# MMCSD1_COMMON_0_CTL_CFG register map
Vendor: Texas Instruments
Registers are 16-bit, read-write, reset 0x0 unless marked. A register's access mark holds for its fields unless they carry their own. Offsets are as the file gives them; [hi:lo] are bit positions; lines under a group give offsets from that group; {n}, {i} and the like mark numbered series.

## MMCSD1_COMMON_0_CTL_CFG (part 3 of 3)
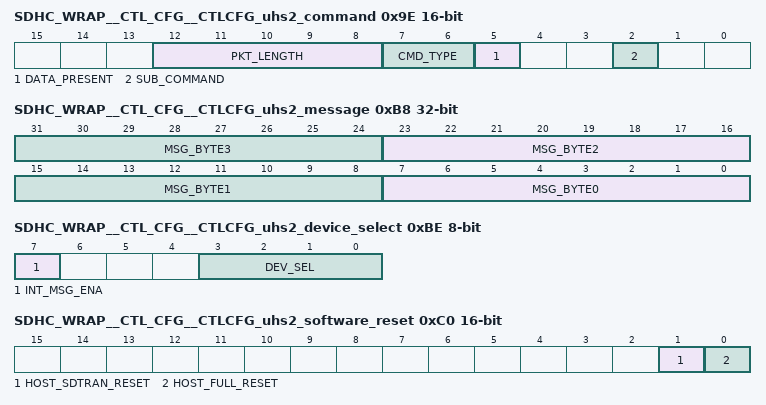
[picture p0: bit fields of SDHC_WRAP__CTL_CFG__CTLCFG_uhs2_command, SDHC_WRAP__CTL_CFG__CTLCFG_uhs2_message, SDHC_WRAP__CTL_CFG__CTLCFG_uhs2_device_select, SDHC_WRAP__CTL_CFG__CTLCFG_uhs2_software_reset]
0x9E SDHC_WRAP__CTL_CFG__CTLCFG_uhs2_command
  [12:8] PKT_LENGTH — A command packet length, which is set in the UHS-II Command Packet register, is set to this register. 00011b - 00000b - 3-0 Bytes [Not used] 00100b - 4 Bytes .......... ...... 10100b - 20 Bytes 11111b 10101b
  [7:6] CMD_TYPE — This field is used to distinguish a spe-cific command like abort command. If this field is set to 00b, the UHS-II RES Packet is stored in UHS-II Response register [0B3h-0A0h]. To avoid overwrit-ing the UHS-II Response register, when this filed is set to 01b, the RES Packet [4 bytes length] of TRANS_ABORT CCMD is stored in the Response regis-ter [013h-010h] and when this filed is set to 10b, the RES Packet [8 bytes length] of memory or SDIO abort com-mand [CMD12 or SDIO Abort com-mand] is stored in the Response register [01Fh-018h]. When this filed is set to 11b, Host Controller controls lane to go into dormant state. '00' Normal Command '01' TRANS_ABORT CCMD '10' CMD12 or SDIO Abort Command '11' Go Dormant Command
  [5] DATA_PRESENT — This bit specifies whether the command is accompanied by data packet.
  [2] SUB_COMMAND — This bit is added from Version 4.10 to distinguish a main command or sub command [Refer to Section 1.17].When issuing a main command, this bit is set to 0 and when issuing a sub com-mand, this bit is set to 1. Setting of this bit is checked by Sub Command Status in the Present State register.
0xA0 SDHC_WRAP__CTL_CFG__CTLCFG_uhs2_response 8-bit ro
  [7:0] RESP_PKT_BYTE — Host Controller saves received UHS-II RES Packet image to this register except the response of an abort command.
0xB4 SDHC_WRAP__CTL_CFG__CTLCFG_uhs2_message_select 8-bit
  [1:0] MSG_SEL — Host Controller holds 4 MSG packets in FIFO buffer.One of 4 MSGs can be read from the UHS-II MSG register [0BB-0B8h] by setting this register.[Assumed for debug usage.] '00' The latest MSG '01' One MSG before '10' Two MSGs before '11' Three MSGs before
0xB8 SDHC_WRAP__CTL_CFG__CTLCFG_uhs2_message 32-bit ro
  [8n+7:8n] MSG_BYTE{n} (n=0..3) — Host Controller holds 4 MSG packets in FIFO buffer. One of 4 MSGs [length is 4 bytes] can be read fromthis register by setting UHS-II MSG Select register. Usually 2 duplicate MSG packets are sent from/toUHS-II card. One of these 2 MSG packets which Host Controller recognizes as valid one is stored in theUHS-II MSG Register.
0xBC SDHC_WRAP__CTL_CFG__CTLCFG_uhs2_device_intr_status access not given
  [15:0] DEV_INT_STS — This register shows receipt of INT MSG from which device and is effective when INT MSG Enable is set to 1 in the UHS- II Device Select register. On receiving INT MSG from a device, Host Controller saves the INT MSG to UHS-II Device Interrupt Code register. A bit of this register, which is corre- spondent to Device ID, is set to 1 and generate Card Interrupt in Normal Interrupt Status register. Writing a bit to 1 clears the status bit [interrupt is treated] and writing a bit to 0 keeps the status value [interrupt is untreated]. If INT MSG Enable is set to 0, this register is cleared to 0 and Host Controller ignores receipt of INT MSG. Effective bit range of this register is determined by Number of Devices Supported in the UHS-II General Capabilities regis-ter. If N devices are supported, bits 1 to N are effective. Then Device ID is supposed to be assigned from 1 sequentially at the UHS-II Initialization. A bit of unsupported Device ID in this register shall be indicated to 0. D00 - Not used [Reserved] D01 - Setting 1 means INT MSG is received from Device ID 1 D02 - Setting 1 means INT MSG is received from Device ID 2 .... ..... D15 - Setting 1 means INT MSG is received from Device ID 15 (access R/W1TC)
0xBE SDHC_WRAP__CTL_CFG__CTLCFG_uhs2_device_select 8-bit
  [7] INT_MSG_ENA — This bit enables receipt of INT MSG. If this bit is set to 1,receipt of INT MSG is informed by Card Interrupt in the Nor-mal Interrupt Status register. If this bit is set to 0, Host Con-troller ignores receipt of INT MSG and may not set the UHS-II Device Interrupt Code register. Support of INT MSG Interrupt is optional. If trying to set this bit to 1 but still this bit is read 0, INT MSG Interrupt is not sup-ported by the Host Controller. In this case, UHS-II Device Interrupt Status register always shall be read 0 and UHS-II Device Interrupt Code register may not be implemented. '0' Disabled '1' Enabled
  [3:0] DEV_SEL — Host Controller holds an INT MSG packet per device. One of INT MSGs [up to 15] can be selected by this field and read from the UHS-II Device Interrupt Code Register [0BFh]. This field is effective when INT MSG Enable is set to 1. The number of devices implemented in the Host Controller is indicated by Number of Devices supported in the UHS-II General Capabilities register. 0h Unselected [Default] 1h INT MSG of Device ID 1 is selected 2h INT MSG of Device ID 2 is selected ..... ..... Fh INT MSG of Device ID 15 is selected
0xBF SDHC_WRAP__CTL_CFG__CTLCFG_uhs2_device_int_code 8-bit ro
  [7:0] DEV_INTR — This register is effective when INT MSG Enable is set to 1 in the UHS-II Device Select register. Host Controller holds an INT MSG packet per device. One of INT MSGs [Code length is 1 byte] up to 15 can be read from this register by select-ing UHS-II Device Select. The number of the registers to hold INT MSGs is determined by Number of Devices Sup-ported in the UHS-II General Capabili-ties register. Device ID is supposed to be assigned from 1 sequentially at the UHS-II Initialization.
0xC0 SDHC_WRAP__CTL_CFG__CTLCFG_uhs2_software_reset
  [1] HOST_SDTRAN_RESET — Host Driver set this bit to 1 to reset SD-TRAN layer when CMD0 is issued to Device or data transfer error occurs. This bit is cleared automatically at completionof SD-TRAN reset. If CMD0 is issued, SD-TRAN Initial- ization sequence from CMD8 is required to use UHS-II mode. Assuming that bus power is maintained and CM-TRAN Initialization is not required. '0' Not Affected '1' Reset SD TRAN Host Controller requires to do followings: [1] SD Clock Enable is maintained.[Continue to provide RCLK]. [2] All setting register is maintained. [3] Internal sequencers are reset to just after power on.be able to issue a command. [4] All Interrupt Status, Status Enable and Signal Enable are cleared. [5] Data transfer is terminated and data in buffer is dis-carded.
  [0] HOST_FULL_RESET — On issuing FULL_RESET CCMD, Host Driver set this bit to 1 to reset Host Controller. This bit is cleared auto-matically at completion of Host Controller reset. Initial- ization sequence from PHY Initialization is required to use UHS-II mode. Assuming that bus power is maintained. Host Controller requires to do followings: [1] SD Clock Enable is cleared. [Internal Clock is still synchronized]. [2] All setting register is cleared. [3] Internal sequencers are reset to just after power on. [4] All Interrupt Status, Status Enable and Signal Enable are cleared.
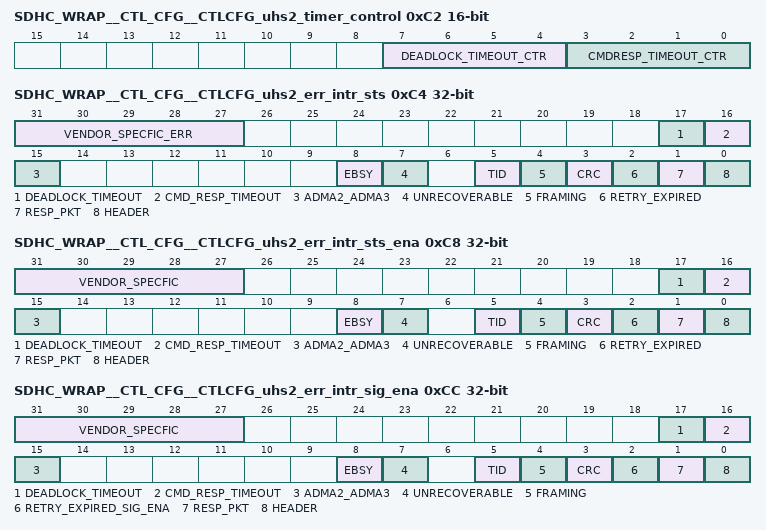
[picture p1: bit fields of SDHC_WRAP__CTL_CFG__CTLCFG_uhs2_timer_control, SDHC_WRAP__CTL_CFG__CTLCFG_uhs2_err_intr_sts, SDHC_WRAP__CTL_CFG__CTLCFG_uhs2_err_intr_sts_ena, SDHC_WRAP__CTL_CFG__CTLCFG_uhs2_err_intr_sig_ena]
0xC2 SDHC_WRAP__CTL_CFG__CTLCFG_uhs2_timer_control
  [7:4] DEADLOCK_TIMEOUT_CTR — This value determines the deadlock period while host expecting to receive a packet [1 second]. Tim-eout clock frequency will be generated by dividing the base clock TMCLK value by this value. When setting this register, prevent inadvertent timeout events by clearing the Timeout for Deadlock [in the UHS-II Error Interrupt Status Enable register] 1111b Reserved 1110b TMCLK x 2^27 .............. .................. 0001b TMCLK x 2^14 0000b TMCLK x 2^13
  [3:0] CMDRESP_TIMEOUT_CTR — This value determines the interval between com-mand packet and response packet [5ms]. Timeout clock frequency will be generated by dividing the base clock TMCLK value by this value. When set-ting this register, prevent inadvertent timeout events by clearing the Timeout for CMD_RES [in the UHS-II Error Interrupt Status Enable register] 1111b Reserved 1110b TMCLK x 2^27 .............. .................. 0001b TMCLK x 2^14 0000b TMCLK x 2^13
0xC4 SDHC_WRAP__CTL_CFG__CTLCFG_uhs2_err_intr_sts 32-bit access not given
  [31:27] VENDOR_SPECFIC_ERR — Vendor may use this field for vendor specific error status. '0' Interrupt is not generated '1' Vendor Specific Error (access R/W1TC)
  [17] DEADLOCK_TIMEOUT — Setting of this bit means that deadlock timeout occurs. Host expects to receive a packet but not received in a specified timeout [1 second]. Timeout value is determined by the setting of Timeout Counter Value for Deadlock in UHS-II Timer Control register. (access R/W1TC)
  [16] CMD_RESP_TIMEOUT — Setting of this bit means that RES Packet timeout occurs. Host expects to receive RES packet but not received in a specified timeout [5ms]. Timeout value is determined by the setting of Timeout Counter Value for CMD_RES in UHS-II Timer Control register. (access R/W1TC)
  [15] ADMA2_ADMA3 — Setting of this bit means that ADMA2/3 Error occurs in UHS-II mode. ADMA2/3 Error Status is indicated to the ADMA Error Status [054h], which is defined in the Host spec 3.00. (access R/W1TC)
  [8] EBSY — On receiving EBSY packet, if the packet indicates an error, this bit is set to 1. Setting of this bit also sets Error Interrupt and Transfer Completer together in the Normal Interrupt Status register. This error check is effective for a command with setting EBSY Wait in the UHS-II Transfer Mode register. (access R/W1TC)
  [7] UNRECOVERABLE — Setting of this bit means that Unrecoverable Error is set in a packet from a device. (access R/W1TC)
  [5] TID — Setting of this bit means that TID Error occurs. (access R/W1TC)
  [4] FRAMING — Setting of this bit means that Framing Error occurs during a packet receiving. (access R/W1TC)
  [3] CRC — Setting of this bit means that CRC Error occurs during a packet receiving. (access R/W1TC)
  [2] RETRY_EXPIRED — Setting of this bit means that Retry Counter Expired Error occurs during data transfer.If this bit is set,either Framing Error or CRC Error in this register shall be set. (access R/W1TC)
  [1] RESP_PKT — Host Controller Version 4.00 supports response error check function to avoid overhead of response error check by Host Driver during DMA execution. If Response Error Check Enable is set to1 in the UHS- II Transfer Mode register, Host Controller Checks R1 or R5 response. If an error is detected in a response,this bit is set to 1. (access R/W1TC)
  [0] HEADER — Setting of this bit means that Header Error occurs in a received packet. (access R/W1TC)
0xC8 SDHC_WRAP__CTL_CFG__CTLCFG_uhs2_err_intr_sts_ena 32-bit
  [31:27] VENDOR_SPECFIC — Setting this bit to 1 enables setting of Vendor Specific Error bit in the UHS-II Error Interrupt Status register. 0h - Status is Disabled 1h - Status is Enabled
  [17] DEADLOCK_TIMEOUT — Setting this bit to 1 enables setting of Timeout for Dead lock bit in the UHS-II Error Interrupt Status register.
  [16] CMD_RESP_TIMEOUT — Setting this bit to 1 enables setting of Timeout for CMD_RES bit in the UHS-II Error Interrupt Status register.
  [15] ADMA2_ADMA3 — Setting this bit to 1 enables setting of ADMA2/3 Error bit in the UHS-II Error Interrupt Status register.
  [8] EBSY — Setting this bit to 1 enables setting of EBSY Error bit in the UHS-II Error Interrupt Status register.
  [7] UNRECOVERABLE — Setting this bit to 1 enables setting of Unrecoverable Error bit in the UHS-II Error Interrupt Status register.
  [5] TID — Setting this bit to 1 enables setting of TID Error bit in the UHS-II Error Interrupt Status register.
  [4] FRAMING — Setting this bit to 1 enables setting of Framing Error bit in the UHS-II Error Interrupt Status register.
  [3] CRC — Setting this bit to 1 enables setting of CRC Error bit in the UHS-II Error Interrupt Status register.
  [2] RETRY_EXPIRED — Setting this bit to 1 enables setting of Retry Expired bit in the UHS-II Error Interrupt Status register.
  [1] RESP_PKT — Setting this bit to 1 enables setting of RES Packet Error bit in the UHS-II Error Interrupt Status register.
  [0] HEADER — Setting this bit to 1 enables setting of Header Error bit in the UHS-II Error Interrupt Status Register.
0xCC SDHC_WRAP__CTL_CFG__CTLCFG_uhs2_err_intr_sig_ena 32-bit
  [31:27] VENDOR_SPECFIC — Setting of a bit to 1 in this field enables generating interrupt signal when corre-spondent bit of Vendor Specific Error is set in the UHS-II Error Interrupt Status Register. 0h - Interrupt Signal is Disabled 1h - Interrupt Signal is Enabled
  [17] DEADLOCK_TIMEOUT — Setting this bit to 1 enables generating interrupt signal when Timeout for Dead lock bit is set in the UHS-II Error InterruptStatus Register.
  [16] CMD_RESP_TIMEOUT — Setting this bit to 1 enables generating interrupt signal when Timeout for CMD_RES bit is set in the UHS-II Error InterruptStatus Register.
  [15] ADMA2_ADMA3 — Setting this bit to 1 enables generating interrupt signal when ADMA2/3 Error bit is set in the UHS-II Error InterruptStatus Register.
  [8] EBSY — Setting this bit to 1 enables generating interrupt signal when EBSY Error bit is set in the UHS-II Error InterruptStatus Register.
  [7] UNRECOVERABLE — Setting this bit to 1 enables generating interrupt signal when Unrecoverable Error bit is set in the UHS-II Error InterruptStatus Register.
  [5] TID — Setting this bit to 1 enables generating interrupt signal when TID Error bit is set in the UHS-II Error InterruptStatus Register.
  [4] FRAMING — Setting this bit to 1 enables generating interrupt signal when Framing Error bit is set in the UHS-II Error InterruptStatus Register.
  [3] CRC — Setting this bit to 1 enables generating interrupt signal when CRC Error bit is set in the UHS-II Error InterruptStatus Register.
  [2] RETRY_EXPIRED_SIG_ENA — Setting this bit to 1 enables generating interrupt signal when Retry Expired bit is set in the UHS-II Error InterruptStatus Register.
  [1] RESP_PKT — Setting this bit to 1 enables generating interrupt signal when RES Packet Error bit is set in the UHS-II Error InterruptStatus Register.
  [0] HEADER — Setting this bit to 1 enables generating interrupt signal when Header Error bit is set in the UHS-II Error Interrupt Status Register.
0xE0 SDHC_WRAP__CTL_CFG__CTLCFG_uhs2_settings_ptr ro reset 0x100
  [15:0] UHS2_SETTINGS_PTR — Pointer for UHS-II Settings Register
0xE2 SDHC_WRAP__CTL_CFG__CTLCFG_uhs2_capabilities_ptr ro reset 0x110
  [15:0] UHS2_CAPABILITIES_PTR — Pointer for UHS-II Capabilities Register
0xE4 SDHC_WRAP__CTL_CFG__CTLCFG_uhs2_test_ptr ro reset 0x120
  [15:0] UHS2_TEST_PTR — Pointer for UHS-II Test Register
0xE6 SDHC_WRAP__CTL_CFG__CTLCFG_shared_bus_ctrl_ptr ro reset 0x130
  [15:0] SHARED_BUS_CTRL_PTR — Pointer for Shared Bus Control Register
0xE8 SDHC_WRAP__CTL_CFG__CTLCFG_vendor_specfic_ptr ro reset 0x140
  [15:0] VENDOR_SPECFIC_PTR — Pointer for Vendor Specific Area
0xF4 SDHC_WRAP__CTL_CFG__CTLCFG_boot_timeout_control 32-bit
  [31:0] DATA_TIMEOUT_CNT — This value determines the interval by which DAT line time-outs are detected during boot operation for eMMC4.4 card.The value is in number of sd clock.
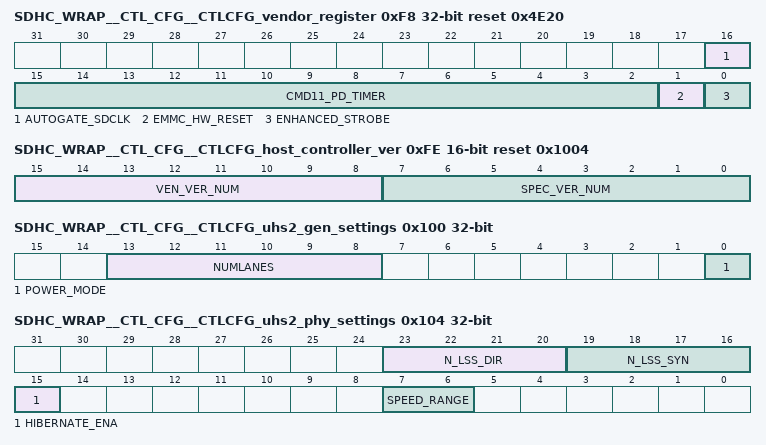
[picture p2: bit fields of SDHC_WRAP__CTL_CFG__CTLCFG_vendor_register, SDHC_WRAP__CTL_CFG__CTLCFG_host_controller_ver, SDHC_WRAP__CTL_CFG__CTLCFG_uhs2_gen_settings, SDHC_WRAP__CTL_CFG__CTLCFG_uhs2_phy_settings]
0xF8 SDHC_WRAP__CTL_CFG__CTLCFG_vendor_register 32-bit reset 0x4E20
  [16] AUTOGATE_SDCLK — If this bit is set, SD CLK will be gated automatically when there is no transfer. This is applicable only for Embedded Device
  [15:2] CMD11_PD_TIMER — cmd11 power-down timer value
  [1] EMMC_HW_RESET — Hardware reset signal is generared for eMMC card when this bit is set
  [0] ENHANCED_STROBE — This bit enables the enhanced strobe logic of the Host Controller
0xFC SDHC_WRAP__CTL_CFG__CTLCFG_slot_int_sts ro
  [7:0] INTR_SIG — These status bits indicate the logical OR of Interrupt signal and Wakeup signal for each slot.
0xFE SDHC_WRAP__CTL_CFG__CTLCFG_host_controller_ver ro reset 0x1004
  [15:8] VEN_VER_NUM — The Vendor Version Number is set to 0x10 [1.0]
  [7:0] SPEC_VER_NUM — This status indicates the Host Controller Spec. Version. The upper and lower 4-bits indicate the version. 00h - SD Host Controller Specification Version 1.00 01h - SD Host Controller Specification Version 2.00 Including the feature of the ADMA and Test Register 02h - SD Host Controller Specification Version 3.00 03h - SD Host Controller Specification Version 4.00 04h - SD Host Controller Specification Version 4.10 'others' Reserved
0x100 SDHC_WRAP__CTL_CFG__CTLCFG_uhs2_gen_settings 32-bit
  [13:8] NUMLANES — The lane configuration of a Host System is set to this field depends on the capability among Host Controller and connected devices. 2 Lanes FD mode is mandatory and the others modes are optional. 0000b - 2 Lanes FD or 2L-HD 0001b - Not Used 0010b - 3 Lanes 2D1U-FD [Embedded] 0011b - 3 Lanes 1D2U-FD [Embedded] 0100b - 4 Lanes 2D2U-FD [Embedded] others - Reserved
  [0] POWER_MODE — This field determines either Fast mode or Low Power mode.Host and all devices connected to the host shall be set to the same mode.
0x104 SDHC_WRAP__CTL_CFG__CTLCFG_uhs2_phy_settings 32-bit
  [23:20] N_LSS_DIR — The largest value of N_LSS_DIR capabilities among the Host Controller and Connected Devices is set to this field. 0h - 8 x16 LSS 1h - 8 x 1 LSS 2h - 8 x 2 LSS 3h - 8 x 3 LSS ...... ...... Fh - 8 x 15 LSS
  [19:16] N_LSS_SYN — The largest value of N_LSS_SYN capabilities among the Host Controller and Connected Devices is set to this field. 0h - 4 x16 LSS 1h - 4 x 1 LSS 2h - 4 x 2 LSS 3h - 4 x 3 LSS ...... ...... Fh - 4 x 15 LSS
  [15] HIBERNATE_ENA — After checking card capability of Hibernate mode, if all devices support Hibernate mode, this bit may be set. This bit determines whether Host remains in Dormant state or goes to Hibernate state. In Hibernate mode, VDD1 Power may be off.
  [7:6] SPEED_RANGE — PLL multiplier is selected by this field.Change of PLL Multiplier is not effective immediately and is applied from exiting Dormant State. '00' Range A [Default] '01' Range B '10' Reserved '11' Reserved
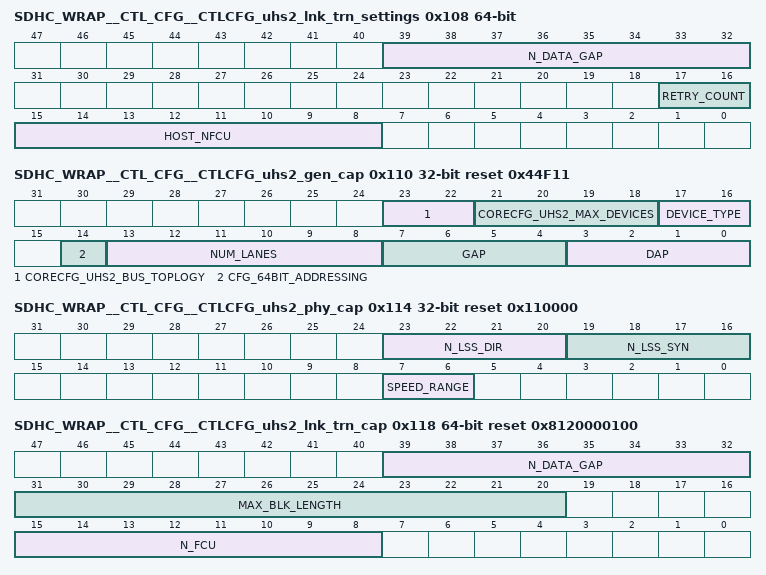
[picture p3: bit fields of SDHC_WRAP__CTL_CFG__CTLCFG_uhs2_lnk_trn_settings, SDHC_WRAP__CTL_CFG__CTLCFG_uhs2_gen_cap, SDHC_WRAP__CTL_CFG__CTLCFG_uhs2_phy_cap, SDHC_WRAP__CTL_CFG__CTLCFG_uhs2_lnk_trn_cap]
0x108 SDHC_WRAP__CTL_CFG__CTLCFG_uhs2_lnk_trn_settings 64-bit
  [39:32] N_DATA_GAP — The largest value of N_DATA_GAP capabilities among the Host Controller and Connected Devices is set to this field. 00h - No Gap 01h - 1 LSS 02h - 2 LSS 03h - 3 LSS ...... ...... FFh - 255 LSS
  [17:16] RETRY_COUNT — Data Burst retry count is set to this field. '00' Retry Disabled '01' 1 time '10' 2 times '11' 3 times
  [15:8] HOST_NFCU — Host Driver sets the number of blocks in Data Burst [Flow Control] to this field.The value shall be smaller than or equal to N_FCU capabilities among the Host Controller and connected card and devices. Setting 1 to 4 blocks is recommended considering buffer size. 00h - 256 Blocks 01h - 1 Block 02h - 2 Blocks 03h - 3 Blocks ...... ...... FFh - 255 Blocks
0x110 SDHC_WRAP__CTL_CFG__CTLCFG_uhs2_gen_cap 32-bit ro reset 0x44F11
  [23:22] CORECFG_UHS2_BUS_TOPLOGY — This field indicates one of bus topologies configured by a Host system. '00' P2P Connection '01' Ring Connection '10' HUB Connection '11' HUB is connected in Ring
  [21:18] CORECFG_UHS2_MAX_DEVICES — This field indicates the maximum number of devices supported by the Host Controller. 0h - Not used 1h - 1 Devices 2h - 2 Devices ..... ....... Fh - 15 Devices
  [17:16] DEVICE_TYPE — This field indicates device type configured by a Host system. '00' Removable Card[P2P] '01' Embedded Devices '10' Embedded Devices+Removable Card '11' Reserved
  [14] CFG_64BIT_ADDRESSING — This field indicates support of 64-bit addressing by the Host Controller. '0' 32-bit Addressing is supported '1' 32-bit and 64-bit Addressing is supported
  [13:8] NUM_LANES — This field indicates support of lanes by the Host Controller.0 mean not supported and 1 means supported. D08 - 2L-HD D09 - 2D1U-FD D10 - 1D2U-FD D11 - 2D2U-FD D12 - Reserved D13 - Reserved
  [7:4] GAP — This field indicates the maximum capability of host power supply for a group configured by a Host system.This field is used to set the argument of DEVICE_INIT CCMD 0h -Not used 1h - 360 mW 2h - 720 mW ..... ....... Fh - 360x15 mW
  [3:0] DAP — This field indicates the maximum capability of host power supply for a device configured by a Host system.This field is used to set the argument of DEVICE_INIT CCMD 0h -360 mW [Default] 1h - 360 mW 2h - 720 mW ..... ....... Fh - 360 x15 mW
0x114 SDHC_WRAP__CTL_CFG__CTLCFG_uhs2_phy_cap 32-bit ro reset 0x110000
  [23:20] N_LSS_DIR — This field indicates the minimum N_LSS_DIR required by the Host Controller. 0h - 4 x16 LSS 1h - 4 x 1 LSS 2h - 4 x 2 LSS 3h - 4 x 3 LSS ...... ...... Fh - 4 x 15 LSS
  [19:16] N_LSS_SYN — This field indicates the minimum N_LSS_SYN required by the Host Controller. 0h - 4 x16 LSS 1h - 4 x 1 LSS 2h - 4 x 2 LSS 3h - 4 x 3 LSS ...... ...... Fh - 4 x 15 LSS
  [7:6] SPEED_RANGE — This field indicates supported Speed Range by the Host Controller '00' Range A [Default] '01' Range A and Range B '10' Reserved '11' Reserved
0x118 SDHC_WRAP__CTL_CFG__CTLCFG_uhs2_lnk_trn_cap 64-bit ro reset 0x8120000100
  [39:32] N_DATA_GAP — This field indicates the minimum number of data gap[DIDL] supported by the Host Controller. 00h - No Gap 01h - 1 LSS 02h - 2 LSS 03h - 3 LSS ...... ...... FFh - 255 LSS
  [31:20] MAX_BLK_LENGTH — This field indicates maximum block length by the Host Controller. 000h - Not Used 001h - 1 byte 002h - 2 bytes ...... ...... 200h - 512 bytes ...... ...... 800h - 2048 bytes 801h-FFFh -Not Used
  [15:8] N_FCU — This field indicates maximum the number of blocks in a Flow Control unit by the Host Controller.This value is determined by supported buffer size. 00h - 256 Blocks 01h - 1 Block 02h - 2 Block 03h - 3 Block ....... FFh - 255 Blocks
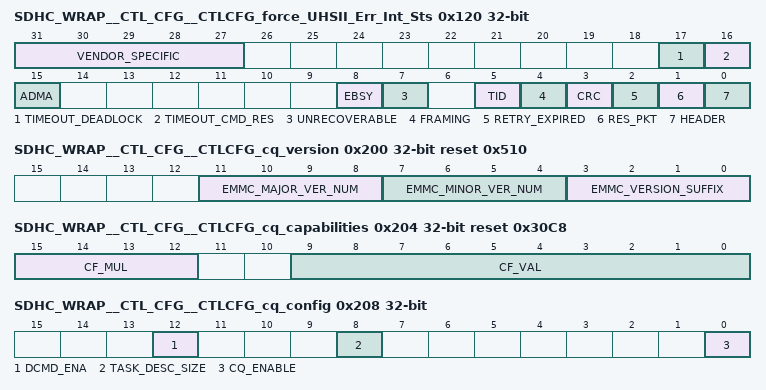
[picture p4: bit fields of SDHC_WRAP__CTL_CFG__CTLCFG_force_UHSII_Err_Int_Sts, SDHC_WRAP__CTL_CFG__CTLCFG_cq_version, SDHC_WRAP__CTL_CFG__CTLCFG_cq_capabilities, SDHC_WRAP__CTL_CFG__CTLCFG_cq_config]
0x120 SDHC_WRAP__CTL_CFG__CTLCFG_force_UHSII_Err_Int_Sts 32-bit wo
  [31:27] VENDOR_SPECIFIC — Force Event for Vendor Specific Error 0h - Not Affected 1h - Vendor Specific Error Status is set
  [17] TIMEOUT_DEADLOCK — Setting this bit forces the Host Controller to set Timeout for Deadlock in the UHS-II Error Interrupt Status register.
  [16] TIMEOUT_CMD_RES — Setting this bit forces the Host Controller to set Timeout for CMD_RES in the UHS-II Error Interrupt Status register.
  [15] ADMA — Setting this bit forces the Host Controller to set ADMA Error in the UHS-II Error Interrupt Status register.
  [8] EBSY — Setting this bit forces the Host Controller to set EBSY Error in the UHS-II Error Interrupt Status register.
  [7] UNRECOVERABLE — Setting this bit forces the Host Controller to set Unrecover-able Error in the UHS-II Error Interrupt Status register.
  [5] TID — Setting this bit forces the Host Controller to set TID Error in the UHS-II Error Interrupt Status register.
  [4] FRAMING — Setting this bit forces the Host Controller to set Framing Error in the UHS-II Error Interrupt Status register.
  [3] CRC — Setting this bit forces the Host Controller to set CRC Error in the UHS-II Error Interrupt Status register.
  [2] RETRY_EXPIRED — Setting this bit forces the Host Controller to set Retry Expired in the UHS-II Error Interrupt Status register.
  [1] RES_PKT — Setting this bit forces the Host Controller to set RES Packet Error in the UHS-II Error Interrupt Status register.
  [0] HEADER — Setting this bit forces the Host Controller to set Header Error in the UHS-II Error Interrupt Status register.
0x200 SDHC_WRAP__CTL_CFG__CTLCFG_cq_version 32-bit ro reset 0x510
  [11:8] EMMC_MAJOR_VER_NUM — eMMC Major Version Number [digit left of decimal point],in BCD format
  [7:4] EMMC_MINOR_VER_NUM — eMMC Minor Version Number [digit right of decimal point], in BCD format
  [3:0] EMMC_VERSION_SUFFIX — eMMC Version Suffix [2nd digit right of decimal point], in BCD format
0x204 SDHC_WRAP__CTL_CFG__CTLCFG_cq_capabilities 32-bit ro reset 0x30C8
  [15:12] CF_MUL — Internal Timer Clock Frequency Multiplier [ITCFMUL] ITCFMUL and ITCFVAL indicate the frequency of the clock used for interrupt coalescing timer and for deter-mining the SQS polling period. See ITCFVAL definition for details. Field Value Description: 0h = 0.001 MHz 1h = 0.01 MHz 2h = 0.1 MHz 3h = 1 MHz 4h = 10 MHz Other values are reserved
  [9:0] CF_VAL — Internal Timer Clock Frequency Value [ITCFVAL] TCFMUL and ITCFVAL indicate the frequency of the clock used for interrupt coalescing timer and for deter-mining the polling period when using periodic SEND_QUEUE_ STATUS [CMD13] polling. The clock frequency is calculated as ITCFVAL*ITCFMUL. For example, to encode 19.2 MHz ITCFVAL shall be C0h [= 192 decimal] and ITCFMUL shall be 2h [0.1 MHz 192 * 0.1 MHz 19.2 MHz]
0x208 SDHC_WRAP__CTL_CFG__CTLCFG_cq_config 32-bit
  [12] DCMD_ENA — Direct Command [DCMD] Enable This bit indicates to the hardware whether the Task Descriptor in slot #31 of the TDL is a Data Transfer Task Descriptor, or a Direct Command Task Descriptor. CQE uses this bit when a task is issued in slot #31, to determine how to decode the Task Descriptor. Bit Value Description 1 = Task descriptor in slot #31 is a DCMD Task Descrip-tor 0 = Task descriptor in slot #31 is a Data Transfer Task Descriptor
  [8] TASK_DESC_SIZE — Task Descriptor Size This bit indicates whether the task descriptor size is 128 bits or 64 bits as detailed in Data Structures section. This bit can only be configured when Command Queueing Enable bit is 0 [command queueing is disabled] Bit Value Description 1 = Task descriptor size is 128 bits 0 = Task descriptor size is 64 bits
  [0] CQ_ENABLE — Command Queueing Enable Software shall write 1 this bit when in order to enable command queueing mode [i.e. enable CQE]. When this bit is 0, CQE is disabled and software controls the eMMC bus using the legacy eMMC host controller. Before software writes 1 to this bit, software shall verify that the eMMC host controller is in idle state and there are no commands or data transfers ongoing. When software wants to exit command queueing mode,it shall clear all previous tasks if such exist before setting this bit to 0.
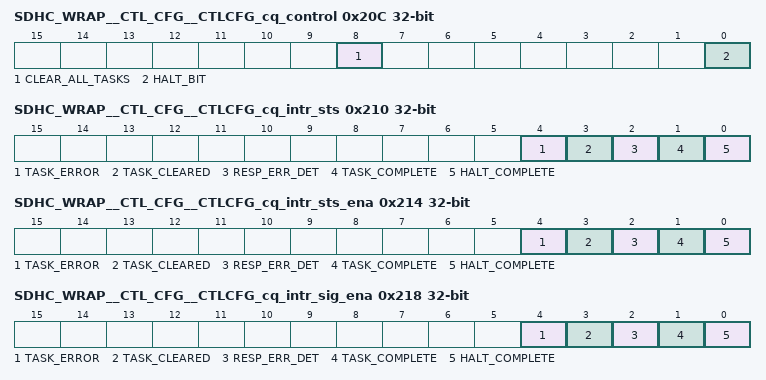
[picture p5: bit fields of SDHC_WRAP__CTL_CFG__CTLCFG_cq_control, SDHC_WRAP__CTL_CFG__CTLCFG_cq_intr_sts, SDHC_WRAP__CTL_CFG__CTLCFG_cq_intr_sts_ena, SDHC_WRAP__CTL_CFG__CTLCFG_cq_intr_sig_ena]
0x20C SDHC_WRAP__CTL_CFG__CTLCFG_cq_control 32-bit
  [8] CLEAR_ALL_TASKS — Clear All Tasks Software shall write 1 this bit when it wants to clear all the tasks sent to the device. This bit can only be written when CQE is in halt state [i.e.Halt bit is 1]. When software writes 1, the value of the register is updated to 1, and CQE shall reset CQTDBR register and all other context information for all unfinished tasks. Then CQE will clear this bit.Software should poll on this bit until it is set to back 0 and may then resume normal operation, by clearing the Halt bit. CQE does not communicate to the device that the tasks were cleared. It is softwares responsibility to order the device to discard the tasks in its queue using CMDQ_TASK_MGMT command. Writing 0 to this register shall have no effect.
  [0] HALT_BIT — Halt Host software shall write 1 to the bit when it wants to acquire software control over the eMMC bus and disable CQE from issuing commands on the bus. For example, issuing a Discard Task command [CMDQ_TASK_MGMT] When software writes 1, CQE shall complete the ongo-ing task if such a task is in progress. Once the task is completed and CQE is in idle state,CQE shall not issue new commands and shall indicate so to software by setting this bit to 1. Software may poll on this bit until it is set to 1, and may only then send commands on the eMMC bus. In order to exit halt state [i.e. resume CQE activity], soft-ware shall clear this bit [write 0]. Writing 0 when thevalue is already 0 shall have no effect.
0x210 SDHC_WRAP__CTL_CFG__CTLCFG_cq_intr_sts 32-bit access not given
  [4] TASK_ERROR — Task Error Interrupt [TERR] This bit is asserted when task error is detected due to invalid task descriptor (access R/W1TC)
  [3] TASK_CLEARED — Task Cleared [TCL] This status bit is asserted [if CQISTE.TCL=1] when a task clear operation is completed by CQE. The com-pleted task clear operation is either an individual task clear [CQTCLR] or clearing of all tasks [CQCTL]. (access R/W1TC)
  [2] RESP_ERR_DET — Response Error Detected Interrupt [RED] This status bit is asserted [if CQISTE.RED=1] when a response is received with an error bit set in the device status field. The contents of the device status field are listed in Section 6.13.Software uses CQRMEM register to configure which device status bit fields may trigger an interrupt, and which are masked. (access R/W1TC)
  [1] TASK_COMPLETE — Task Complete Interrupt [TCC] This status bit is asserted [if CQISTE.TCC=1] when atleast one of the following two conditions are met: [1] A task is completed and the INT bit is set in its Task Descriptor [2] Interrupt caused by Interrupt Coalescing logic [see Section C.4.9] (access R/W1TC)
  [0] HALT_COMPLETE — Halt Complete Interrupt [HAC] This status bit is asserted [if CQISTE.HAC=1] when halt bit in CQCTL register transitions from 0 to 1 indicating that host controller has completed its current ongoing task and has entered halt state. (access R/W1TC)
0x214 SDHC_WRAP__CTL_CFG__CTLCFG_cq_intr_sts_ena 32-bit
  [4] TASK_ERROR — Task Error Interrupt Status Enable 1 = CQIS.TERR will be set when its interrupt condition is active 0 = CQIS.TERR is disabled
  [3] TASK_CLEARED — Task Cleared Status Enable [TCL] 1 = CQIS.TCL will be set when its interrupt condition is active 0 = CQIS.TCL is disabled
  [2] RESP_ERR_DET — Response Error Detected Status Enable [RED] 1 = CQIS.RED will be set when its interrupt condition is active 0 = CQIS.RED is disabled
  [1] TASK_COMPLETE — Task Complete Status Enable [TCC] 1 = CQIS.TCC will be set when its interrupt condition is active 0 = CQIS.TCC is disabled
  [0] HALT_COMPLETE — Halt Complete Status Enable [HAC] 1 = CQIS.HAC will be set when its interrupt condition is active 0 = CQIS.HAC is disabled
0x218 SDHC_WRAP__CTL_CFG__CTLCFG_cq_intr_sig_ena 32-bit
  [4] TASK_ERROR — Task Error Interrupt Signal Enable [TERR] When set and CQIS.TERR is asserted, the CQE shall generate an interrupt
  [3] TASK_CLEARED — Task Cleared Signal Enable [TCL] When set and CQIS.TCL is asserted, the CQE shall generate an interrupt
  [2] RESP_ERR_DET — Response Error Detected Signal Enable [TCC] When set and CQIS.RED is asserted, the CQE shall generate an interrupt
  [1] TASK_COMPLETE — Task Complete Signal Enable [TCC] When set and CQIS.TCC is asserted, the CQE shall generate an interrupt
  [0] HALT_COMPLETE — Halt Complete Signal Enable [HAC] When set and CQIS.HAC is asserted, the CQE shall generate an interrupt
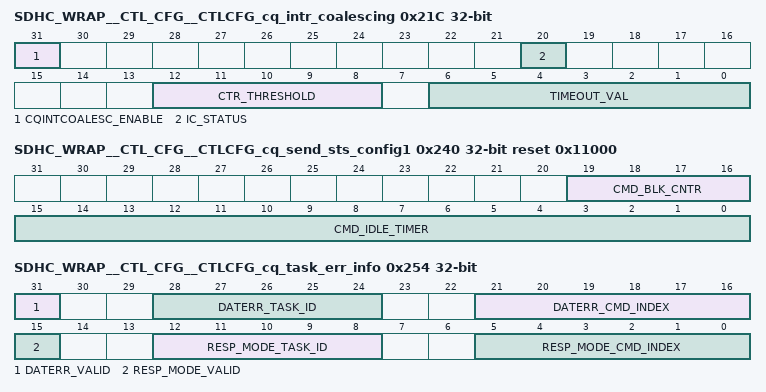
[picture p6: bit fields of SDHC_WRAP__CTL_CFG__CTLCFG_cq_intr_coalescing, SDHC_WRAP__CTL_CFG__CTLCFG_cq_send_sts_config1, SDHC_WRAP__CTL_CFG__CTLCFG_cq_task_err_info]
0x21C SDHC_WRAP__CTL_CFG__CTLCFG_cq_intr_coalescing 32-bit access per field
  [31] CQINTCOALESC_ENABLE rw — When set to 0 by software, command responses are neither counted nor timed. Interrupts are still triggered by completion of tasks with INT=1 in the Task Descriptor. When set to 1, the interrupt coalescing mechanism is enabled and coalesced interrupts are generated.
  [20] IC_STATUS ro — This bit indicates to software whether any tasks [with INT=0] have completed and counted towards interrupt coalescing [i.e., ICSB is set if and only if IC counter > 0]. Bit Value Description 1 = At least one task completion has been counted [IC counter >0] 0 = No task completions have occurred since last counter reset [IC counter =0]
  [12:8] CTR_THRESHOLD rw — Interrupt Coalescing Counter Threshold [ICCTH]: Software uses this field to configure the number of task completions [only tasks with INT=0 in the Task Descriptor] which are required in order to generate an interrupt. Counter Operation: As data transfer tasks with INT=0 complete, they are counted by CQE. The counter is reset by software during the interrupt service routine. The counter stops counting when it reaches the value configured in ICCTH. The maximum allowed value is 31 NOTE : When ICCTH is 0, task completions are not counted, and counting-based interrupts are not generated.In order to write to this field, the ICCTHWEN bit must be set at the same write operation.
  [6:0] TIMEOUT_VAL rw — Interrupt Coalescing Timeout Value [ICTOVAL]: Software uses this field to configure the maximum time allowed between the completion of a task on the bus and the generation of an interrupt. Timer Operation: The timer is reset by software during the interrupt service routine. It starts running when a data transfer task with INT=0 is completed, after the timer was reset. When the timer reaches the value configured in ICTOVAL field it generates an interrupt and stops. The timers unit is equal to 1024 clock periods of the clock whose frequency is specified in the Internal Timer Clock Frequency field CQCAP register.The minimum value is 01h [1024 clock periods] and the maximum value is 7Fh [127*1024 clock periods]. For example, a CQCAP field value of 0 indicates a 19.2 MHz clock frequency [period = 52.08 ns]. If the setting in ICTOVAL is 10h, the calculated polling period is 16*1024*52.08 ns= 853.33 us NOTE: When ICTOVAL is 0, the timer is not running, and timer-based interrupts are not generated. In order to write to this field, the ICTOVALWEN bit must be set at the same write operation.
0x220 SDHC_WRAP__CTL_CFG__CTLCFG_cq_tdl_base_addr 32-bit
  [31:0] CQTDLBA_LO — Task Descriptor List Base Address [TDLBA] This register stores the LSB bits [bits 31:0] of the byte address of the head of the Task Descriptor List in system memory. The size of the task descriptor list is 32 * [Task Descrip-tor size + Transfer Descriptor size] as configured by Host driver. This address shall be set on Byte1 KByte boundary.: The lower 10 bits of this register shall be set to 0 by software and shall be ignored by CQE.
0x224 SDHC_WRAP__CTL_CFG__CTLCFG_cq_tdl_base_addr_upbits 32-bit
  [31:0] CQTDLBA_HI — Task Descriptor List Base Address [TDLBA] This register stores the MSB bits [bits 63:32] of the byte address of the head of the Task Descriptor List in system memory. The size of the task descriptor list is 32 * [Task Descrip-tor size + Transfer Descriptor size] as configured by Host driver. This register is reserved when using 32-bit addressing mode.
0x228 SDHC_WRAP__CTL_CFG__CTLCFG_cq_task_door_bell 32-bit access not given
  [31:0] CQTDB_VAL — Command Queueing Task Doorbell Software shall configure TDLBA and TDLBAU, and enable CQE in CQCFG before using this register. Writing 1 to bit n of this register triggers CQE to start pro-cessing the task encoded in slot n of the TDL. CQE always processes tasks in-order according to the order submitted to the list by CQTDBR write transac-tions. CQE processes Data Transfer tasks by reading the Task Descriptor and sending QUEUED_TASK_PARAMS[CMD44] and QUEUED_TASK_ADDRESS [CMD45]commands to the device. CQE processes DCMD tasks [in slot #31, when enabled]by reading the Task Descriptor, and generating the com-mand encoded by its index and argument. The corresponding bit is cleared to 0 by CQE in one of the following events: [a] When a task execution is completed [with success or error] [b] The task is cleared using CQTCLR register [c] All tasks are cleared using CQCTL register [d] CQE is disabled using CQCFG register Software may initiate multiple tasks at the same time [batch submission] by writing 1 to multiple bits of this register in the same transaction. In the case of batch submission: CQE shall process the tasks in order of the task index,starting with the lowest index. If one or more tasks in the batch are marked with QBR,the ordering of execution will be based on said process-ing order. Writing 0 by software shall have no impact on the hard-ware, and will not change the value of the register bit. (access R/W1TS)
0x22C SDHC_WRAP__CTL_CFG__CTLCFG_cq_task_comp_notif 32-bit access not given
  [31:0] CQTCN_VAL — CQE shall set bit n of this register [at the same time it clears bit n of CQTDBR] when a task execution is com-pleted [with success or error]. When receiving interrupt for task completion, software may read this register to know which tasks have finished. After reading this register, software may clear the rele-vant bit fields by writing 1 to the corresponding bits. (access R/W1TC)
0x230 SDHC_WRAP__CTL_CFG__CTLCFG_cq_dev_queue_status 32-bit ro
  [31:0] CQDQ_STS — Every time the Host controller receives a queue status register [QSR] from the device, it updates this register with the response of status command, i.e. the devices queue status.
0x234 SDHC_WRAP__CTL_CFG__CTLCFG_cq_dev_pending_tasks 32-bit ro
  [31:0] CQDP_TSKS — Bit n of this register is set if and only if QUEUED_TASK_PARAMS [CMD44] and QUEUED_TASK_ADDRESS [CMD45] were sent for this specific task and if this task hasnt been executed yet.CQE shall set this bit after receiving a successful response for CMD45. CQE shall clear this bit after the task has completed execution.Software needs to read this register in the task-discard procedure, when the controller is halted, to determine if the task is queued in the device. If the task is queued,the driver sends a CMDQ_TASK_MGMT [CMD48] to the device ordering it to discard the task. Then software clears the task in the CQE. Only then the software orders CQE to resume its operation using CQCTL register.
0x238 SDHC_WRAP__CTL_CFG__CTLCFG_cq_task_clear 32-bit
  [31:0] CQTCLR — Writing 1 to bit n of this register orders CQE to clear a task which software has previously issued.This bit can only be written when CQE is in Halt state as indicated in CQCFG register Halt bit.When software writes 1 to a bit in this register,CQE updates the value to 1, and starts clearing the data structures related to the task. CQE clears the bit fields [sets a value of 0] in CQTCLR and in CQTDBR once clear operation is complete.Software should poll on the CQTCLR until it is cleared to verify clear operation was complete.Writing to this register only clears the task in the CQE and does not have impact on the device. In order to dis-card the task in the device, host software shall send CMDQ_TASK _MGMT while CQE is still in Halt state.Host driver is not allowed to use this register to clear multiple tasks at the same time. Clearing multiple tasks can be done using CQCTL register.Writing 0 to a register bit shall have no impact.
0x240 SDHC_WRAP__CTL_CFG__CTLCFG_cq_send_sts_config1 32-bit reset 0x11000
  [19:16] CMD_BLK_CNTR — This field indicates to CQE when to send SEND_QUEUE_STATUS [CMD13] command to inquire the status of the devices task queue.A value of n means CQE shall send status command on the CMD line, during the transfer of data block BLOCK_CNT-n, on the data lines, where BLOCK_CNT is the number of blocks in the current transaction.A value of 0 means that SEND_QUEUE_STATUS [CMD13] command shall not be sent during the transac-tion. Instead it will be sent only when the data lines are idle.A value of 1 means that STATUS command is to be sent during the last block of the transaction.
  [15:0] CMD_IDLE_TIMER — This field indicates to CQE the polling period to use when using periodic SEND_QUEUE_STATUS [CMD13] polling.Periodic polling is used when tasks are pending in the device, but no data transfer is in progress. When a SEND_QUEUE_STATUS response indicating that no task is ready for execution, CQE counts the configured time until it issues the next SEND_QUEUE_STATUS.Timer units are clock periods of theclock whose fre-quency is specified in the Internal Timer Clock Fre-quency field CQCAP register.The minimum value is 0001h [1 clock period] and the maximum value is FFFFh [65535 clock periods]. Default interval is: 4096 clock periods. For example, a CQCAP field value of 0 indicates a 19.2 MHz clock frequency [period = 52.08 ns]. If the setting in CQSST is 1000h, the calcu.lated polling period is 4096*52.08 ns= 213.33 us.
0x244 SDHC_WRAP__CTL_CFG__CTLCFG_cq_send_sts_config2 32-bit
  [15:0] QUEUE_RCA — This field provides CQE with the contents of the 16-bit RCA field in SEND_QUEUE_ STATUS [CMD13] com-mand. argument. CQE shall copy this field to bits 31:16 of the argument when transmitting SEND_ QUEUE_STATUS [CMD13] command.
0x248 SDHC_WRAP__CTL_CFG__CTLCFG_cq_dcmd_response 32-bit ro
  [31:0] LAST_RESP — This register contains the response of the command generated by the last direct-command [DCMD] task which was sent.CQE shall update this register when it receives the response for a DCMD task. This register is considered valid only after bit 31 of CQT-DBR register is cleared by CQE.
0x250 SDHC_WRAP__CTL_CFG__CTLCFG_cq_resp_err_mask 32-bit reset 0xFDF9A080
  [31:0] CQRMEM — This bit is used as in interrupt mask on the device status filed which is received in R1/R1b responses.Bit Value Description [for any bit i]:1 = When a R1/R1b response is received, with bit i in the device status set, a RED interrupt is generated 0 = When a R1/R1b response is received, bit i in the device status is ignored The reset value of this register is set to trigger an inter-rupt on all Error type bits in the device status, as defined in Section 6.13.NOTE: Responses to CMD13 [SQS] encode the QSR,so they are ignored by this logic
0x254 SDHC_WRAP__CTL_CFG__CTLCFG_cq_task_err_info 32-bit ro
  [31] DATERR_VALID — Data Transfer Error Fields Valid This bit is updated when an error is detected by CQE, or indicated by eMMC controller. If a data transfer is in progress when the error is detected/indicated, the bit is set to 1. If a no data transfer is in progress when the error is detected/indicated, the bit is cleared to 0.
  [28:24] DATERR_TASK_ID — Data Transfer Error Task ID This field indicates the ID of the task which was executed on the data lines when an error occurred. The field is updated if a data transfer is in progress when an error is detected by CQE, or indicated by eMMC controller
  [21:16] DATERR_CMD_INDEX — Data Transfer Error Command Index This field indicates the index of the command which was executed on the data lines when an error occurred. The index shall be set to EXECUTE_READ_TASK[CMD46] or EXECUTE_WRITE_TASK [CMD47] accord-ing to the data direction. The field is updated if a data transfer is in progress when an error is detected by CQE, or indicated by eMMC controller.
  [15] RESP_MODE_VALID — Response Mode Error Fields Valid This bit is updated when an error is detected by CQE, or indicated by eMMC controller. If a command transaction is in progress when the error is detected/indicated, the bit is set to 1. If a no command transaction is in progress when the error is detected/indicated, the bit is cleared to 0.
  [12:8] RESP_MODE_TASK_ID — Response Mode Error Task ID This field indicates the ID of the task which was executed on the command line when an error occurred. The field is updated if a command transaction is in progress when an error is detected by CQE, or indicated by eMMC controller.
  [5:0] RESP_MODE_CMD_INDEX — Response Mode Error Command Index This field indicates the index of the command which was executed on the command line when an error occurred. The field is updated if a command transaction is in progress when an error is detected by CQE, or indicated by eMMC controller.
0x258 SDHC_WRAP__CTL_CFG__CTLCFG_cq_cmd_resp_index 32-bit ro
  [5:0] LAST_CRI — This field stores the index of the last received command response. CQE shall update the value every time a com-mand response is received.
0x25C SDHC_WRAP__CTL_CFG__CTLCFG_cq_cmd_resp_arg 32-bit ro
  [31:0] LAST_CRA — This field stores the argument of the last received com-mand. CQE shall update the value every time a com-mand response is received.
0x260 SDHC_WRAP__CTL_CFG__CTLCFG_cq_error_task_id 32-bit ro
  [4:0] TERR_ID — Task Error ID
